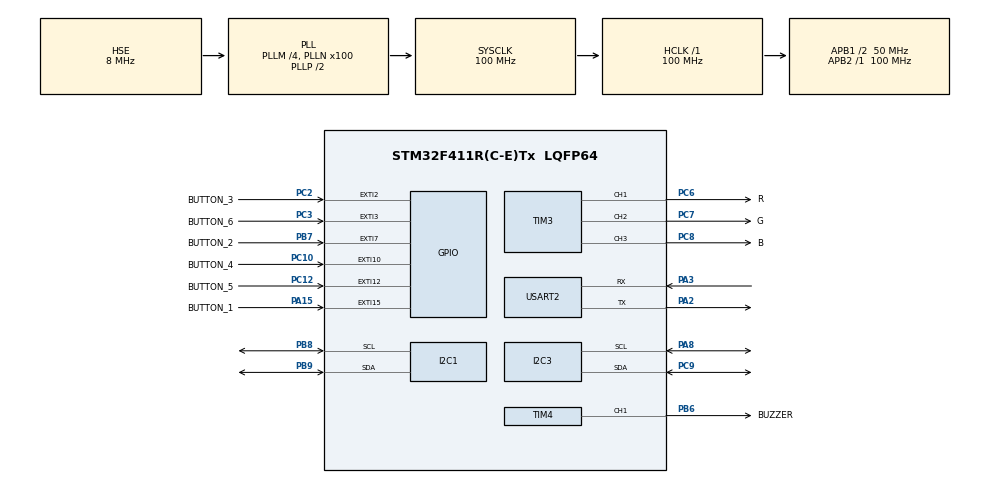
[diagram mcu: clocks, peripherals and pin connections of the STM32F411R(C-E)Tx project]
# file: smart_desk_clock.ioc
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Dma.I2C3_TX.2.Direction=DMA_MEMORY_TO_PERIPH
Dma.I2C3_TX.2.FIFOMode=DMA_FIFOMODE_DISABLE
Dma.I2C3_TX.2.Instance=DMA1_Stream4
Dma.I2C3_TX.2.MemDataAlignment=DMA_MDATAALIGN_BYTE
Dma.I2C3_TX.2.MemInc=DMA_MINC_ENABLE
Dma.I2C3_TX.2.Mode=DMA_NORMAL
Dma.I2C3_TX.2.PeriphDataAlignment=DMA_PDATAALIGN_BYTE
Dma.I2C3_TX.2.PeriphInc=DMA_PINC_DISABLE
Dma.I2C3_TX.2.Priority=DMA_PRIORITY_LOW
Dma.Request0=USART2_RX
Dma.Request1=USART2_TX
Dma.Request2=I2C3_TX
Dma.USART2_RX.0.Direction=DMA_PERIPH_TO_MEMORY
Dma.USART2_RX.0.FIFOMode=DMA_FIFOMODE_DISABLE
Dma.USART2_RX.0.Instance=DMA1_Stream5
Dma.USART2_RX.0.MemDataAlignment=DMA_MDATAALIGN_BYTE
Dma.USART2_RX.0.MemInc=DMA_MINC_ENABLE
Dma.USART2_RX.0.Mode=DMA_CIRCULAR
Dma.USART2_RX.0.PeriphDataAlignment=DMA_PDATAALIGN_BYTE
Dma.USART2_RX.0.PeriphInc=DMA_PINC_DISABLE
Dma.USART2_RX.0.Priority=DMA_PRIORITY_LOW
Dma.USART2_TX.1.Direction=DMA_MEMORY_TO_PERIPH
Dma.USART2_TX.1.FIFOMode=DMA_FIFOMODE_DISABLE
Dma.USART2_TX.1.Instance=DMA1_Stream6
Dma.USART2_TX.1.MemDataAlignment=DMA_MDATAALIGN_BYTE
Dma.USART2_TX.1.MemInc=DMA_MINC_ENABLE
Dma.USART2_TX.1.Mode=DMA_CIRCULAR
Dma.USART2_TX.1.PeriphDataAlignment=DMA_PDATAALIGN_BYTE
Dma.USART2_TX.1.PeriphInc=DMA_PINC_DISABLE
Dma.USART2_TX.1.Priority=DMA_PRIORITY_LOW
I2C1.I2C_Mode=I2C_Fast
I2C3.I2C_Mode=I2C_Fast
Mcu.Family=STM32F4
Mcu.Name=STM32F411R(C-E)Tx
Mcu.Package=LQFP64
NVIC.DMA1_Stream4_IRQn=true\:0\:0\:false\:false\:true\:false\:true\:true
NVIC.DMA1_Stream5_IRQn=true\:0\:0\:false\:false\:true\:false\:true\:true
NVIC.DMA1_Stream6_IRQn=true\:0\:0\:false\:false\:true\:false\:true\:true
NVIC.EXTI15_10_IRQn=true\:14\:0\:true\:false\:true\:true\:true\:true
NVIC.EXTI2_IRQn=true\:0\:0\:false\:false\:true\:true\:true\:true
NVIC.EXTI3_IRQn=true\:0\:0\:false\:false\:true\:true\:true\:true
NVIC.EXTI9_5_IRQn=true\:0\:0\:false\:false\:true\:true\:true\:true
NVIC.I2C3_EV_IRQn=true\:14\:0\:true\:false\:true\:true\:true\:true
NVIC.PriorityGroup=NVIC_PRIORITYGROUP_4
NVIC.TIM1_BRK_TIM9_IRQn=true\:1\:0\:true\:false\:true\:true\:true\:true
NVIC.TIM1_TRG_COM_TIM11_IRQn=true\:15\:0\:true\:false\:true\:true\:true\:true
NVIC.TIM3_IRQn=true\:0\:0\:false\:false\:true\:true\:true\:true
NVIC.TIM4_IRQn=true\:0\:0\:false\:false\:true\:true\:true\:true
NVIC.USART2_IRQn=true\:0\:0\:false\:false\:true\:true\:true\:true
PA13.Mode=Serial_Wire
PA13.Signal=SYS_JTMS-SWDIO
PA14.Mode=Serial_Wire
PA14.Signal=SYS_JTCK-SWCLK
PA15.GPIO_Label=BUTTON_1
PA15.GPIO_ModeDefaultEXTI=GPIO_MODE_IT_FALLING
PA15.GPIO_PuPd=GPIO_PULLUP
PA15.Signal=GPXTI15
PA2.Mode=Asynchronous
PA2.Signal=USART2_TX
PA3.Mode=Asynchronous
PA3.Signal=USART2_RX
PA8.GPIO_Pu=GPIO_PULLUP
PA8.Mode=I2C
PA8.Signal=I2C3_SCL
PB6.GPIO_Label=BUZZER
PB6.Signal=S_TIM4_CH1
PB7.GPIO_Label=BUTTON_2
PB7.GPIO_ModeDefaultEXTI=GPIO_MODE_IT_FALLING
PB7.GPIO_PuPd=GPIO_PULLUP
PB7.Signal=GPXTI7
PB8.GPIO_Pu=GPIO_PULLUP
PB8.Mode=I2C
PB8.Signal=I2C1_SCL
PB9.GPIO_Pu=GPIO_PULLUP
PB9.Mode=I2C
PB9.Signal=I2C1_SDA
PC10.GPIO_Label=BUTTON_4
PC10.GPIO_ModeDefaultEXTI=GPIO_MODE_IT_FALLING
PC10.GPIO_PuPd=GPIO_PULLUP
PC10.Signal=GPXTI10
PC12.GPIO_Label=BUTTON_5
PC12.GPIO_ModeDefaultEXTI=GPIO_MODE_IT_FALLING
PC12.GPIO_PuPd=GPIO_PULLUP
PC12.Signal=GPXTI12
PC2.GPIO_Label=BUTTON_3
PC2.GPIO_ModeDefaultEXTI=GPIO_MODE_IT_FALLING
PC2.GPIO_PuPd=GPIO_PULLUP
PC2.Signal=GPXTI2
PC3.GPIO_Label=BUTTON_6
PC3.GPIO_ModeDefaultEXTI=GPIO_MODE_IT_FALLING
PC3.GPIO_PuPd=GPIO_PULLUP
PC3.Signal=GPXTI3
PC6.GPIO_Label=R
PC6.GPIO_ModeDefaultPP=GPIO_MODE_AF_PP
PC6.GPIO_PuPd=GPIO_PULLDOWN
PC6.Signal=S_TIM3_CH1
PC7.GPIO_Label=G
PC7.GPIO_PuPd=GPIO_PULLDOWN
PC7.Signal=S_TIM3_CH2
PC8.GPIO_Label=B
PC8.GPIO_PuPd=GPIO_PULLDOWN
PC8.Signal=S_TIM3_CH3
PC9.GPIO_Pu=GPIO_PULLUP
PC9.Mode=I2C
PC9.Signal=I2C3_SDA
PH0\ -\ OSC_IN.Mode=HSE-External-Oscillator
PH0\ -\ OSC_IN.Signal=RCC_OSC_IN
PH1\ -\ OSC_OUT.Mode=HSE-External-Oscillator
PH1\ -\ OSC_OUT.Signal=RCC_OSC_OUT
ProjectManager.HeapSize=0x200
ProjectManager.StackSize=0x400
ProjectManager.TargetToolchain=STM32CubeIDE
RCC.48MHZClocksFreq_Value=50000000
RCC.AHBFreq_Value=100000000
RCC.APB1CLKDivider=RCC_HCLK_DIV2
RCC.APB1Freq_Value=50000000
RCC.APB1TimFreq_Value=100000000
RCC.APB2Freq_Value=100000000
RCC.APB2TimFreq_Value=100000000
RCC.CortexFreq_Value=100000000
RCC.HCLKFreq_Value=100000000
RCC.HSE_VALUE=8000000
RCC.HSI_VALUE=16000000
RCC.LSE_VALUE=32768
RCC.PLLM=4
RCC.PLLN=100
RCC.PLLSourceVirtual=RCC_PLLSOURCE_HSE
RCC.RCC_RTC_Clock_Source=RCC_RTCCLKSOURCE_LSI
RCC.RCC_RTC_Clock_SourceVirtual=RCC_RTCCLKSOURCE_LSI
RCC.SYSCLKFreq_VALUE=100000000
RCC.SYSCLKSource=RCC_SYSCLKSOURCE_PLLCLK
RCC.VCOOutputFreq_Value=200000000
SH.S_TIM3_CH1.0=TIM3_CH1,PWM Generation1 CH1
SH.S_TIM3_CH2.0=TIM3_CH2,PWM Generation2 CH2
SH.S_TIM3_CH3.0=TIM3_CH3,PWM Generation3 CH3
SH.S_TIM4_CH1.0=TIM4_CH1,PWM Generation1 CH1
TIM11.AutoReloadPreload=TIM_AUTORELOAD_PRELOAD_ENABLE
TIM11.Period=10000-1
TIM11.Prescaler=10000-1
TIM3.Channel-PWM\ Generation1\ CH1=TIM_CHANNEL_1
TIM3.Channel-PWM\ Generation2\ CH2=TIM_CHANNEL_2
TIM3.Channel-PWM\ Generation3\ CH3=TIM_CHANNEL_3
TIM4.Channel-PWM\ Generation1\ CH1=TIM_CHANNEL_1
USART2.VirtualMode=VM_ASYNC
VP_TIM11_VS_ClockSourceINT.Mode=Enable_Timer
VP_TIM3_VS_ClockSourceINT.Mode=Internal
VP_TIM4_VS_ClockSourceINT.Mode=Internal
VP_TIM9_VS_ClockSourceINT.Mode=Internal
board=custom

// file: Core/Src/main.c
/* USER CODE BEGIN Header */
/**
 ******************************************************************************
 * @file           : main.c
 * @brief          : Main program body
 ******************************************************************************
 * @attention
 *
 * <h2><center>&copy; Copyright (c) 2023 STMicroelectronics.
 * All rights reserved.</center></h2>
 *
 * This software component is licensed by ST under BSD 3-Clause license,
 * the "License"; You may not use this file except in compliance with the
 * License. You may obtain a copy of the License at:
 *                        opensource.org/licenses/BSD-3-Clause
 *
 ******************************************************************************
 */
/* USER CODE END Header */
#include "main.h"

/* USER CODE BEGIN Includes */
#include "system_manager.h"
/* USER CODE END Includes */

I2C_HandleTypeDef hi2c1;
I2C_HandleTypeDef hi2c3;
DMA_HandleTypeDef hdma_i2c3_tx;

TIM_HandleTypeDef htim3;
TIM_HandleTypeDef htim4;
TIM_HandleTypeDef htim9;
TIM_HandleTypeDef htim11;

UART_HandleTypeDef huart2;
DMA_HandleTypeDef  hdma_usart2_rx;
DMA_HandleTypeDef  hdma_usart2_tx;

/* USER CODE BEGIN PV */
static button_name_t button_state;
/* USER CODE END PV */

void        SystemClock_Config(void);
static void MX_GPIO_Init(void);
static void MX_DMA_Init(void);
static void MX_USART2_UART_Init(void);
static void MX_I2C1_Init(void);
static void MX_I2C3_Init(void);
static void MX_TIM3_Init(void);
static void MX_TIM9_Init(void);
static void MX_TIM4_Init(void);
static void MX_TIM11_Init(void);

int main(void)
{

    /* MCU Configuration--------------------------------------------------------*/

    /* Reset of all peripherals, Initializes the Flash interface and the Systick. */
    HAL_Init();

    /* Configure the system clock */
    SystemClock_Config();

    /* Initialize all configured peripherals */
    MX_GPIO_Init();
    MX_DMA_Init();
    MX_USART2_UART_Init();
    MX_I2C1_Init();
    MX_I2C3_Init();
    MX_TIM3_Init();
    MX_TIM9_Init();
    MX_TIM4_Init();
    MX_TIM11_Init();
    /* USER CODE BEGIN 2 */
    system_manager_init();
    /* USER CODE END 2 */

    /* Infinite loop */
    while (1)
    {

        /* USER CODE BEGIN 3 */
        system_manager_run(&button_state);
    }
    /* USER CODE END 3 */
}

void SystemClock_Config(void)
{
    RCC_OscInitTypeDef RCC_OscInitStruct = { 0 };
    RCC_ClkInitTypeDef RCC_ClkInitStruct = { 0 };

    /** Configure the main internal regulator output voltage
     */
    __HAL_RCC_PWR_CLK_ENABLE();
    __HAL_PWR_VOLTAGESCALING_CONFIG(PWR_REGULATOR_VOLTAGE_SCALE1);

    /** Initializes the RCC Oscillators according to the specified parameters
     * in the RCC_OscInitTypeDef structure.
     */
    RCC_OscInitStruct.OscillatorType = RCC_OSCILLATORTYPE_HSE;
    RCC_OscInitStruct.HSEState       = RCC_HSE_ON;
    RCC_OscInitStruct.PLL.PLLState   = RCC_PLL_ON;
    RCC_OscInitStruct.PLL.PLLSource  = RCC_PLLSOURCE_HSE;
    RCC_OscInitStruct.PLL.PLLM       = 4;
    RCC_OscInitStruct.PLL.PLLN       = 100;
    RCC_OscInitStruct.PLL.PLLP       = RCC_PLLP_DIV2;
    RCC_OscInitStruct.PLL.PLLQ       = 4;
    if (HAL_RCC_OscConfig(&RCC_OscInitStruct) != HAL_OK)
    {
        Error_Handler();
    }

    /** Initializes the CPU, AHB and APB buses clocks
     */
    RCC_ClkInitStruct.ClockType      = RCC_CLOCKTYPE_HCLK | RCC_CLOCKTYPE_SYSCLK | RCC_CLOCKTYPE_PCLK1 | RCC_CLOCKTYPE_PCLK2;
    RCC_ClkInitStruct.SYSCLKSource   = RCC_SYSCLKSOURCE_PLLCLK;
    RCC_ClkInitStruct.AHBCLKDivider  = RCC_SYSCLK_DIV1;
    RCC_ClkInitStruct.APB1CLKDivider = RCC_HCLK_DIV2;
    RCC_ClkInitStruct.APB2CLKDivider = RCC_HCLK_DIV1;

    if (HAL_RCC_ClockConfig(&RCC_ClkInitStruct, FLASH_LATENCY_3) != HAL_OK)
    {
        Error_Handler();
    }
}

static void MX_I2C1_Init(void)
{

    hi2c1.Instance             = I2C1;
    hi2c1.Init.ClockSpeed      = 400000;
    hi2c1.Init.DutyCycle       = I2C_DUTYCYCLE_2;
    hi2c1.Init.OwnAddress1     = 0;
    hi2c1.Init.AddressingMode  = I2C_ADDRESSINGMODE_7BIT;
    hi2c1.Init.DualAddressMode = I2C_DUALADDRESS_DISABLE;
    hi2c1.Init.OwnAddress2     = 0;
    hi2c1.Init.GeneralCallMode = I2C_GENERALCALL_DISABLE;
    hi2c1.Init.NoStretchMode   = I2C_NOSTRETCH_DISABLE;
    if (HAL_I2C_Init(&hi2c1) != HAL_OK)
    {
        Error_Handler();
    }
}

static void MX_I2C3_Init(void)
{

    hi2c3.Instance             = I2C3;
    hi2c3.Init.ClockSpeed      = 400000;
    hi2c3.Init.DutyCycle       = I2C_DUTYCYCLE_2;
    hi2c3.Init.OwnAddress1     = 0;
    hi2c3.Init.AddressingMode  = I2C_ADDRESSINGMODE_7BIT;
    hi2c3.Init.DualAddressMode = I2C_DUALADDRESS_DISABLE;
    hi2c3.Init.OwnAddress2     = 0;
    hi2c3.Init.GeneralCallMode = I2C_GENERALCALL_DISABLE;
    hi2c3.Init.NoStretchMode   = I2C_NOSTRETCH_DISABLE;
    if (HAL_I2C_Init(&hi2c3) != HAL_OK)
    {
        Error_Handler();
    }
}

static void MX_TIM3_Init(void)
{

    TIM_ClockConfigTypeDef  sClockSourceConfig = { 0 };
    TIM_MasterConfigTypeDef sMasterConfig      = { 0 };
    TIM_OC_InitTypeDef      sConfigOC          = { 0 };

    htim3.Instance               = TIM3;
    htim3.Init.Prescaler         = 0;
    htim3.Init.CounterMode       = TIM_COUNTERMODE_UP;
    htim3.Init.Period            = 65535;
    htim3.Init.ClockDivision     = TIM_CLOCKDIVISION_DIV1;
    htim3.Init.AutoReloadPreload = TIM_AUTORELOAD_PRELOAD_DISABLE;
    if (HAL_TIM_Base_Init(&htim3) != HAL_OK)
    {
        Error_Handler();
    }
    sClockSourceConfig.ClockSource = TIM_CLOCKSOURCE_INTERNAL;
    if (HAL_TIM_ConfigClockSource(&htim3, &sClockSourceConfig) != HAL_OK)
    {
        Error_Handler();
    }
    if (HAL_TIM_PWM_Init(&htim3) != HAL_OK)
    {
        Error_Handler();
    }
    sMasterConfig.MasterOutputTrigger = TIM_TRGO_RESET;
    sMasterConfig.MasterSlaveMode     = TIM_MASTERSLAVEMODE_DISABLE;
    if (HAL_TIMEx_MasterConfigSynchronization(&htim3, &sMasterConfig) != HAL_OK)
    {
        Error_Handler();
    }
    sConfigOC.OCMode     = TIM_OCMODE_PWM1;
    sConfigOC.Pulse      = 0;
    sConfigOC.OCPolarity = TIM_OCPOLARITY_HIGH;
    sConfigOC.OCFastMode = TIM_OCFAST_DISABLE;
    if (HAL_TIM_PWM_ConfigChannel(&htim3, &sConfigOC, TIM_CHANNEL_1) != HAL_OK)
    {
        Error_Handler();
    }
    if (HAL_TIM_PWM_ConfigChannel(&htim3, &sConfigOC, TIM_CHANNEL_2) != HAL_OK)
    {
        Error_Handler();
    }
    if (HAL_TIM_PWM_ConfigChannel(&htim3, &sConfigOC, TIM_CHANNEL_3) != HAL_OK)
    {
        Error_Handler();
    }
    HAL_TIM_MspPostInit(&htim3);
}

static void MX_TIM4_Init(void)
{

    TIM_ClockConfigTypeDef  sClockSourceConfig = { 0 };
    TIM_MasterConfigTypeDef sMasterConfig      = { 0 };
    TIM_OC_InitTypeDef      sConfigOC          = { 0 };

    htim4.Instance               = TIM4;
    htim4.Init.Prescaler         = 0;
    htim4.Init.CounterMode       = TIM_COUNTERMODE_UP;
    htim4.Init.Period            = 65535;
    htim4.Init.ClockDivision     = TIM_CLOCKDIVISION_DIV1;
    htim4.Init.AutoReloadPreload = TIM_AUTORELOAD_PRELOAD_DISABLE;
    if (HAL_TIM_Base_Init(&htim4) != HAL_OK)
    {
        Error_Handler();
    }
    sClockSourceConfig.ClockSource = TIM_CLOCKSOURCE_INTERNAL;
    if (HAL_TIM_ConfigClockSource(&htim4, &sClockSourceConfig) != HAL_OK)
    {
        Error_Handler();
    }
    if (HAL_TIM_PWM_Init(&htim4) != HAL_OK)
    {
        Error_Handler();
    }
    sMasterConfig.MasterOutputTrigger = TIM_TRGO_RESET;
    sMasterConfig.MasterSlaveMode     = TIM_MASTERSLAVEMODE_DISABLE;
    if (HAL_TIMEx_MasterConfigSynchronization(&htim4, &sMasterConfig) != HAL_OK)
    {
        Error_Handler();
    }
    sConfigOC.OCMode     = TIM_OCMODE_PWM1;
    sConfigOC.Pulse      = 0;
    sConfigOC.OCPolarity = TIM_OCPOLARITY_HIGH;
    sConfigOC.OCFastMode = TIM_OCFAST_DISABLE;
    if (HAL_TIM_PWM_ConfigChannel(&htim4, &sConfigOC, TIM_CHANNEL_1) != HAL_OK)
    {
        Error_Handler();
    }
    HAL_TIM_MspPostInit(&htim4);
}

static void MX_TIM9_Init(void)
{

    TIM_ClockConfigTypeDef sClockSourceConfig = { 0 };

    htim9.Instance               = TIM9;
    htim9.Init.Prescaler         = 0;
    htim9.Init.CounterMode       = TIM_COUNTERMODE_UP;
    htim9.Init.Period            = 65535;
    htim9.Init.ClockDivision     = TIM_CLOCKDIVISION_DIV1;
    htim9.Init.AutoReloadPreload = TIM_AUTORELOAD_PRELOAD_DISABLE;
    if (HAL_TIM_Base_Init(&htim9) != HAL_OK)
    {
        Error_Handler();
    }
    sClockSourceConfig.ClockSource = TIM_CLOCKSOURCE_INTERNAL;
    if (HAL_TIM_ConfigClockSource(&htim9, &sClockSourceConfig) != HAL_OK)
    {
        Error_Handler();
    }
}

static void MX_TIM11_Init(void)
{

    htim11.Instance               = TIM11;
    htim11.Init.Prescaler         = 10000 - 1;
    htim11.Init.CounterMode       = TIM_COUNTERMODE_UP;
    htim11.Init.Period            = 10000 - 1;
    htim11.Init.ClockDivision     = TIM_CLOCKDIVISION_DIV1;
    htim11.Init.AutoReloadPreload = TIM_AUTORELOAD_PRELOAD_ENABLE;
    if (HAL_TIM_Base_Init(&htim11) != HAL_OK)
    {
        Error_Handler();
    }
}

static void MX_USART2_UART_Init(void)
{

    huart2.Instance          = USART2;
    huart2.Init.BaudRate     = 115200;
    huart2.Init.WordLength   = UART_WORDLENGTH_8B;
    huart2.Init.StopBits     = UART_STOPBITS_1;
    huart2.Init.Parity       = UART_PARITY_NONE;
    huart2.Init.Mode         = UART_MODE_TX_RX;
    huart2.Init.HwFlowCtl    = UART_HWCONTROL_NONE;
    huart2.Init.OverSampling = UART_OVERSAMPLING_16;
    if (HAL_UART_Init(&huart2) != HAL_OK)
    {
        Error_Handler();
    }
}

static void MX_DMA_Init(void)
{
    /* DMA controller clock enable */
    __HAL_RCC_DMA1_CLK_ENABLE();

    /* DMA interrupt init */
    /* DMA1_Stream4_IRQn interrupt configuration */
    HAL_NVIC_SetPriority(DMA1_Stream4_IRQn, 0, 0);
    HAL_NVIC_EnableIRQ(DMA1_Stream4_IRQn);
    /* DMA1_Stream5_IRQn interrupt configuration */
    HAL_NVIC_SetPriority(DMA1_Stream5_IRQn, 0, 0);
    HAL_NVIC_EnableIRQ(DMA1_Stream5_IRQn);
    /* DMA1_Stream6_IRQn interrupt configuration */
    HAL_NVIC_SetPriority(DMA1_Stream6_IRQn, 0, 0);
    HAL_NVIC_EnableIRQ(DMA1_Stream6_IRQn);
}

static void MX_GPIO_Init(void)
{
    GPIO_InitTypeDef GPIO_InitStruct = { 0 };

    /* GPIO Ports Clock Enable */
    __HAL_RCC_GPIOH_CLK_ENABLE();
    __HAL_RCC_GPIOC_CLK_ENABLE();
    __HAL_RCC_GPIOA_CLK_ENABLE();
    __HAL_RCC_GPIOB_CLK_ENABLE();

    /*Configure GPIO pins : BUTTON_3_Pin BUTTON_6_Pin BUTTON_4_Pin BUTTON_5_Pin */
    GPIO_InitStruct.Pin  = BUTTON_3_Pin | BUTTON_6_Pin | BUTTON_4_Pin | BUTTON_5_Pin;
    GPIO_InitStruct.Mode = GPIO_MODE_IT_FALLING;
    GPIO_InitStruct.Pull = GPIO_PULLUP;
    HAL_GPIO_Init(GPIOC, &GPIO_InitStruct);

    /*Configure GPIO pin : BUTTON_1_Pin */
    GPIO_InitStruct.Pin  = BUTTON_1_Pin;
    GPIO_InitStruct.Mode = GPIO_MODE_IT_FALLING;
    GPIO_InitStruct.Pull = GPIO_PULLUP;
    HAL_GPIO_Init(BUTTON_1_GPIO_Port, &GPIO_InitStruct);

    /*Configure GPIO pin : BUTTON_2_Pin */
    GPIO_InitStruct.Pin  = BUTTON_2_Pin;
    GPIO_InitStruct.Mode = GPIO_MODE_IT_FALLING;
    GPIO_InitStruct.Pull = GPIO_PULLUP;
    HAL_GPIO_Init(BUTTON_2_GPIO_Port, &GPIO_InitStruct);

    /* EXTI interrupt init*/
    HAL_NVIC_SetPriority(EXTI2_IRQn, 0, 0);
    HAL_NVIC_EnableIRQ(EXTI2_IRQn);

    HAL_NVIC_SetPriority(EXTI3_IRQn, 0, 0);
    HAL_NVIC_EnableIRQ(EXTI3_IRQn);

    HAL_NVIC_SetPriority(EXTI9_5_IRQn, 0, 0);
    HAL_NVIC_EnableIRQ(EXTI9_5_IRQn);

    HAL_NVIC_SetPriority(EXTI15_10_IRQn, 14, 0);
    HAL_NVIC_EnableIRQ(EXTI15_10_IRQn);
}

void Error_Handler(void)
{
    __disable_irq();
    while (1)
    {
    }
}
